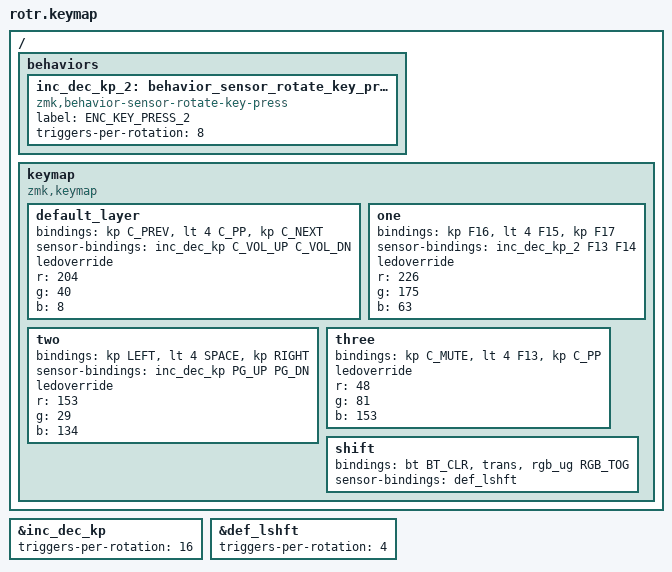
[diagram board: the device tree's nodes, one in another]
#include <behaviors.dtsi>
#include <dt-bindings/zmk/keys.h>
#include <dt-bindings/zmk/rgb.h>
#include <dt-bindings/zmk/bt.h>

/ {
    behaviors {
        inc_dec_kp_2: behavior_sensor_rotate_key_press_2 {
            compatible = "zmk,behavior-sensor-rotate-key-press";
            label = "ENC_KEY_PRESS_2";
            triggers-per-rotation = <8>;
            #sensor-binding-cells = <2>;
        };
    };
};

&inc_dec_kp {
	triggers-per-rotation = <16>;
};
&def_lshft {
	triggers-per-rotation = <4>;
};

/ {
	keymap {
		compatible = "zmk,keymap";

		default_layer {
			//PREV | PLAY/PAUSE | NEXT
			bindings = <&kp C_PREV &lt 4 C_PP &kp C_NEXT>;
			sensor-bindings = <&inc_dec_kp C_VOL_UP C_VOL_DN>;
			ledoverride;
			r = <204>;
			g = <40>;
			b = <8>;
		};
		one {
			// DEBUGGING
			//PREV | PLAY/PAUSE | NEXT
			bindings = <&kp F16 &lt 4 F15 &kp F17>;
			sensor-bindings = <&inc_dec_kp_2 F13 F14>;
			ledoverride;
			r = <226>;
			g = <175>;
			b = <63>;
		};
		two {
			//PREV | PLAY/PAUSE | NEXT
			bindings = <&kp LEFT &lt 4 SPACE &kp RIGHT>;
			sensor-bindings = <&inc_dec_kp PG_UP PG_DN>;
			ledoverride;
			r = <153>;
			g = <29>;
			b = <134>;
		};
		three {
			//PREV | PLAY/PAUSE | NEXT
			bindings = <&kp C_MUTE &lt 4 F13 &kp C_PP>;
			ledoverride;
			r = <48>;
			g = <81>;
			b = <153>;
		};
		shift {
			//PREV | PLAY/PAUSE | NEXT
			bindings = <&bt BT_CLR &trans &rgb_ug RGB_TOG>;
			sensor-bindings = <&def_lshft>;
		};
	};
};
